# STM32WBA55 register map
File version: 1.0
CPU: CM33 r0p1, little endian, MPU, FPU, 4 interrupt priority bits
Registers are 32-bit, read-write, reset 0x0 unless marked. A register's access mark holds for its fields unless they carry their own. Offsets are from the block's base; [hi:lo] are bit positions; {n}, {i} and the like mark numbered series; 'fields as' and 'values as' point back to an identical list.

## I2C — Inter-integrated circuit
Base 0x40005400
Same registers: I2C3 0x46002800, SEC_I2C1 0x50005400, SEC_I2C3 0x56002800
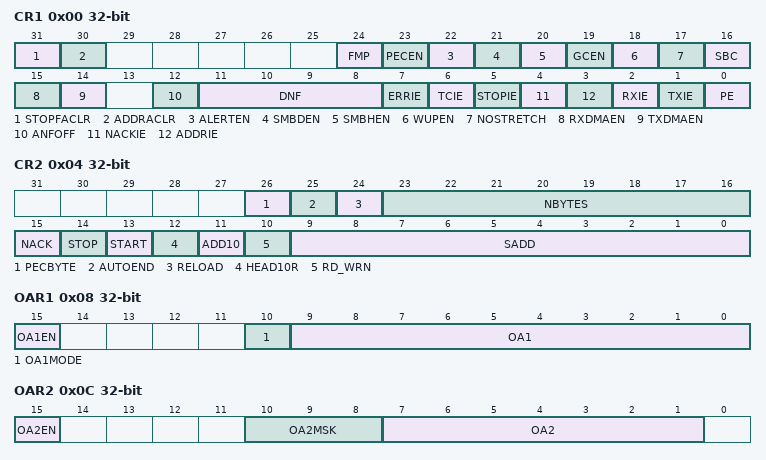
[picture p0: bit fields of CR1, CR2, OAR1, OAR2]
0x00 CR1 — I2C control register 1
  [31] STOPFACLR — STOP detection flag (STOPF) automatic clear
    0=Disabled (STOPF flag is set by hardware, cleared by software); 1=Enabled (STOPF flag remains cleared by hardware)
  [30] ADDRACLR — Address match flag (ADDR) automatic clear
    0=Disabled (ADDR flag is set by hardware, cleared by software); 1=Enabled (ADDR flag remains cleared by hardware)
  [24] FMP — Fast-mode Plus 20 mA drive enable
    0=Disabled (20 mA I/O drive disabled); 1=Enabled (20 mA I/O drive enabled)
  [23] PECEN — PEC enable Note: If the SMBus feature is not supported, this bit is reserved and forced by hardware to '0'. Refer to Section 52.3: FMPI2C implementation.
    0=Disabled (PEC calculation disabled); 1=Enabled (PEC calculation enabled)
  [22] ALERTEN — SMBus alert enable Note: When ALERTEN=0, the SMBA pin can be used as a standard GPIO. Note: If the SMBus feature is not supported, this bit is reserved and forced by hardware to '0'. Refer to Section 52.3: FMPI2C implementation.
    0=Disabled (In device mode (SMBHEN=Disabled) Releases SMBA pin high and Alert Response Address Header disabled (0001100x) followed by NACK. In host mode (SMBHEN=Enabled) SMBus Alert pin (SMBA) not supported); 1=Enabled (In device mode (SMBHEN=Disabled) Drives SMBA pin low and Alert Response Address Header enabled (0001100x) followed by ACK.In host mode (SMBHEN=Enabled) SMBus Alert pin (SMBA) supported)
  [21] SMBDEN — SMBus device default address enable Note: If the SMBus feature is not supported, this bit is reserved and forced by hardware to '0'. Refer to Section 52.3: FMPI2C implementation.
    0=Disabled (Device default address disabled. Address 0b1100001x is NACKed); 1=Enabled (Device default address enabled. Address 0b1100001x is ACKed)
  [20] SMBHEN — SMBus host address enable Note: If the SMBus feature is not supported, this bit is reserved and forced by hardware to '0'. Refer to Section 52.3: FMPI2C implementation.
    0=Disabled (Host address disabled. Address 0b0001000x is NACKed); 1=Enabled (Host address enabled. Address 0b0001000x is ACKed)
  [19] GCEN — General call enable
    0=Disabled (General call disabled. Address 0b00000000 is NACKed); 1=Enabled (General call enabled. Address 0b00000000 is ACKed)
  [18] WUPEN — Wakeup from Stop mode enable Note: If the Wakeup from Stop mode feature is not supported, this bit is reserved and forced by hardware to '0'. Refer to Section 52.3: FMPI2C implementation. Note: WUPEN can be set only when DNF = '0000'
    0=Disabled (Wakeup from Stop mode disabled); 1=Enabled (Wakeup from Stop mode enabled)
  [17] NOSTRETCH — Clock stretching disable This bit is used to disable clock stretching in slave mode. It must be kept cleared in master mode. Note: This bit can only be programmed when the I2C is disabled (PE = 0).
    0=Enabled (Clock stretching enabled); 1=Disabled (Clock stretching disabled)
  [16] SBC — Slave byte control This bit is used to enable hardware byte control in slave mode.
    0=Disabled (Slave byte control disabled); 1=Enabled (Slave byte control enabled)
  [15] RXDMAEN — DMA reception requests enable
    0=Disabled (DMA mode disabled for reception); 1=Enabled (DMA mode enabled for reception)
  [14] TXDMAEN — DMA transmission requests enable
    0=Disabled (DMA mode disabled for transmission); 1=Enabled (DMA mode enabled for transmission)
  [12] ANFOFF — Analog noise filter OFF Note: This bit can only be programmed when the I2C is disabled (PE = 0).
    0=Enabled (Analog noise filter enabled); 1=Disabled (Analog noise filter disabled)
  [11:8] DNF — Digital noise filter These bits are used to configure the digital noise filter on SDA and SCL input. The digital filter, filters spikes with a length of up to DNF[3:0] * tsubI2CCLK/sub sub.../sub Note: If the analog filter is also enabled, the digital filter is added to the analog filter. Note: This filter can only be programmed when the I2C is disabled (PE = 0).
    0=NoFilter (Digital filter disabled); {v}=Filter{v} (Digital filter enabled and filtering capability up to {v} tI2CCLK) (v=1..15)
  [7] ERRIE — Error interrupts enable Note: Any of these errors generate an interrupt: Note: Arbitration Loss (ARLO) Note: Bus Error detection (BERR) Note: Overrun/Underrun (OVR) Note: Timeout detection (TIMEOUT) Note: PEC error detection (PECERR) Note: Alert pin event detection (ALERT)
    0=Disabled (Error detection interrupts disabled); 1=Enabled (Error detection interrupts enabled)
  [6] TCIE — Transfer Complete interrupt enable Note: Any of these events generate an interrupt: Note: Transfer Complete (TC) Note: Transfer Complete Reload (TCR)
    0=Disabled (Transfer Complete interrupt disabled); 1=Enabled (Transfer Complete interrupt enabled)
  [5] STOPIE — Stop detection Interrupt enable
    0=Disabled (Stop detection (STOPF) interrupt disabled); 1=Enabled (Stop detection (STOPF) interrupt enabled)
  [4] NACKIE — Not acknowledge received Interrupt enable
    0=Disabled (Not acknowledge (NACKF) received interrupts disabled); 1=Enabled (Not acknowledge (NACKF) received interrupts enabled)
  [3] ADDRIE — Address match Interrupt enable (slave only)
    0=Disabled (Address match (ADDR) interrupts disabled); 1=Enabled (Address match (ADDR) interrupts enabled)
  [2] RXIE — RX Interrupt enable
    0=Disabled (Receive (RXNE) interrupt disabled); 1=Enabled (Receive (RXNE) interrupt enabled)
  [1] TXIE — TX Interrupt enable
    0=Disabled (Transmit (TXIS) interrupt disabled); 1=Enabled (Transmit (TXIS) interrupt enabled)
  [0] PE — Peripheral enable Note: When PE = 0, the I2C SCL and SDA lines are released. Internal state machines and status bits are put back to their reset value. When cleared, PE must be kept low for at least 3 APB clock cycles.
    0=Disabled (Peripheral disabled); 1=Enabled (Peripheral enabled)
0x04 CR2 — I2C control register 2
  [26] PECBYTE write-1-sets — Packet error checking byte This bit is set by software, and cleared by hardware when the PEC is transferred, or when a STOP condition or an Address matched is received, also when PE = 0. Note: Writing '0' to this bit has no effect. Note: This bit has no effect when RELOAD is set. Note: This bit has no effect is slave mode when SBC=0. Note: If the SMBus feature is not supported, this bit is reserved and forced by hardware to '0'. Refer to Section 52.3: FMPI2C implementation.
    on read: 0=No PEC transfer; 1=Pec (PEC transmission/reception is requested) | on write: 1=Pec (PEC transmission/reception is requested)
  [25] AUTOEND — Automatic end mode (master mode) This bit is set and cleared by software. Note: This bit has no effect in slave mode or when the RELOAD bit is set.
    0=Software end mode: TC flag is set when NBYTES data are transferred, stretching SCL low; 1=Automatic end mode: a STOP condition is automatically sent when NBYTES data are transferred
  [24] RELOAD — NBYTES reload mode This bit is set and cleared by software.
    0=Completed (The transfer is completed after the NBYTES data transfer (STOP or RESTART will follow)); 1=NotCompleted (The transfer is not completed after the NBYTES data transfer (NBYTES will be reloaded))
  [23:16] NBYTES — Number of bytes The number of bytes to be transmitted/received is programmed there. This field is don't care in slave mode with SBC=0. Note: Changing these bits when the START bit is set is not allowed.
  [15] NACK write-1-sets — NACK generation (slave mode) The bit is set by software, cleared by hardware when the NACK is sent, or when a STOP condition or an Address matched is received, or when PE = 0. Note: Writing '0' to this bit has no effect. Note: This bit is used in slave mode only: in master receiver mode, NACK is automatically generated after last byte preceding STOP or RESTART condition, whatever the NACK bit value. Note: When an overrun occurs in slave receiver NOSTRETCH mode, a NACK is automatically generated whatever the NACK bit value. Note: When hardware PEC checking is enabled (PECBYTE=1), the PEC acknowledge value does not depend on the NACK value.
    on read: 0=Ack (an ACK is sent after current received byte); 1=Nack (a NACK is sent after current received byte) | on write: 1=Nack (a NACK is sent after current received byte)
  [14] STOP write-1-sets — Stop generation (master mode) The bit is set by software, cleared by hardware when a STOP condition is detected, or when PE = 0. In Master Mode: Note: Writing '0' to this bit has no effect.
    on read: 0=No Stop generation; 1=Stop generation after current byte transfer | on write: 1=Stop generation after current byte transfer
  [13] START write-1-sets — Start generation This bit is set by software, and cleared by hardware after the Start followed by the address sequence is sent, by an arbitration loss, by an address matched in slave mode, by a timeout error detection, or when PE = 0. If the I2C is already in master mode with AUTOEND = 0, setting this bit generates a Repeated Start condition when RELOAD=0, after the end of the NBYTES transfer. Otherwise setting this bit generates a START condition once the bus is free. Note: Writing '0' to this bit has no effect. Note: The START bit can be set even if the bus is BUSY or I2C is in slave mode. Note: This bit has no effect when RELOAD is set.
    on read: 0=No Start generation; 1=Start (Restart/Start generation) | on write: 1=Start (Restart/Start generation)
  [12] HEAD10R — 10-bit address header only read direction (master receiver mode) Note: Changing this bit when the START bit is set is not allowed.
    0=Complete (The master sends the complete 10 bit slave address read sequence); 1=Partial (The master only sends the 1st 7 bits of the 10 bit address, followed by Read direction)
  [11] ADD10 — 10-bit addressing mode (master mode) Note: Changing this bit when the START bit is set is not allowed.
    0=Bit7 (The master operates in 7-bit addressing mode); 1=Bit10 (The master operates in 10-bit addressing mode)
  [10] RD_WRN — Transfer direction (master mode) Note: Changing this bit when the START bit is set is not allowed.
    0=Write (Master requests a write transfer); 1=Read (Master requests a read transfer)
  [9:0] SADD — Slave address (master mode) In 7-bit addressing mode (ADD10 = 0): SADD[7:1] should be written with the 7-bit slave address to be sent. The bits SADD[9], SADD[8] and SADD[0] are don't care. In 10-bit addressing mode (ADD10 = 1): SADD[9:0] should be written with the 10-bit slave address to be sent. Note: Changing these bits when the START bit is set is not allowed.
0x08 OAR1 — I2C own address 1 register
  [15] OA1EN — Own Address 1 enable
    0=Disabled (Own address 1 disabled. The received slave address OA1 is NACKed); 1=Enabled (Own address 1 enabled. The received slave address OA1 is ACKed)
  [10] OA1MODE — Own Address 1 10-bit mode Note: This bit can be written only when OA1EN=0.
    0=Bit7 (Own address 1 is a 7-bit address); 1=Bit10 (Own address 1 is a 10-bit address)
  [9:0] OA1 — Interface own slave address 7-bit addressing mode: OA1[7:1] contains the 7-bit own slave address. The bits OA1[9], OA1[8] and OA1[0] are don't care. 10-bit addressing mode: OA1[9:0] contains the 10-bit own slave address. Note: These bits can be written only when OA1EN=0.
0x0C OAR2 — I2C own address 2 register
  [15] OA2EN — Own Address 2 enable
    0=Disabled (Own address 2 disabled. The received slave address OA2 is NACKed); 1=Enabled (Own address 2 enabled. The received slave address OA2 is ACKed)
  [10:8] OA2MSK — Own Address 2 masks Note: These bits can be written only when OA2EN=0. Note: As soon as OA2MSK is not equal to 0, the reserved I2C addresses (0b0000xxx and 0b1111xxx) are not acknowledged even if the comparison matches.
    0=NoMask; 1=Mask1 (OA2[1] is masked and don’t care. Only OA2[7:2] are compared); {v}=Mask{v} (OA2[{v}:1] are masked and don’t care. Only OA2[7:{v+1}] are compared) (v=2..5); 6=Mask6 (OA2[6:1] are masked and don’t care. Only OA2[7] is compared.); 7=Mask7 (OA2[7:1] are masked and don’t care. No comparison is done, and all (except reserved) 7-bit received addresses are acknowledged)
  [7:1] OA2 — Interface address 7-bit addressing mode: 7-bit address Note: These bits can be written only when OA2EN=0.
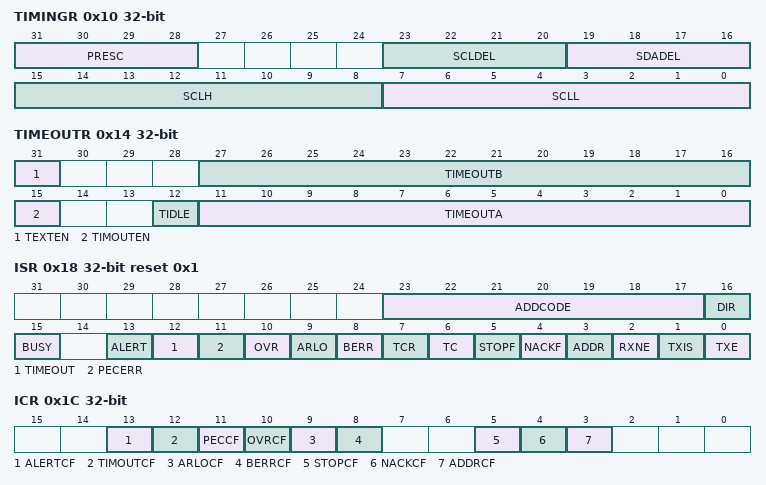
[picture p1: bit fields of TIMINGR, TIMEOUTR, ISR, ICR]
0x10 TIMINGR — I2C timing register
  [31:28] PRESC — Timing prescaler This field is used to prescale i2c_ker_ck in order to generate the clock period tsubPRESC /subused for data setup and hold counters (refer to FMPI2C timings on page 1928) and for SCL high and low level counters (refer to FMPI2C master initialization on page 1951). tsubPRESC /sub= (PRESC+1) x tsubI2CCLK/sub
  [23:20] SCLDEL — Data setup time This field is used to generate a delay tsubSCLDEL /subbetween SDA edge and SCL rising edge. In master mode and in slave mode with NOSTRETCH = 0, the SCL line is stretched low during tsubSCLDEL/sub. tsubSCLDEL /sub= (SCLDEL+1) x tsubPRESC/sub Note: tsubSCLDEL/sub is used to generate tsubSU:DAT /subtiming.
  [19:16] SDADEL — Data hold time This field is used to generate the delay tsubSDADEL /subbetween SCL falling edge and SDA edge. In master mode and in slave mode with NOSTRETCH = 0, the SCL line is stretched low during tsubSDADEL/sub. tsubSDADEL/sub= SDADEL x tsubPRESC/sub Note: SDADEL is used to generate tsubHD:DAT /subtiming.
  [15:8] SCLH — SCL high period (master mode) This field is used to generate the SCL high period in master mode. tsubSCLH /sub= (SCLH+1) x tsubPRESC/sub Note: SCLH is also used to generate tsubSU:STO /suband tsubHD:STA /subtiming.
  [7:0] SCLL — SCL low period (master mode) This field is used to generate the SCL low period in master mode. tsubSCLL /sub= (SCLL+1) x tsubPRESC/sub Note: SCLL is also used to generate tsubBUF /suband tsubSU:STA /subtimings.
0x14 TIMEOUTR — I2C timeout register
  [31] TEXTEN — Extended clock timeout enable
    0=Disabled (Extended clock timeout detection is disabled); 1=Enabled (Extended clock timeout detection is enabled)
  [27:16] TIMEOUTB — Bus timeout B This field is used to configure the cumulative clock extension timeout: In master mode, the master cumulative clock low extend time (tsubLOW:MEXT/sub) is detected In slave mode, the slave cumulative clock low extend time (tsubLOW:SEXT/sub) is detected tsubLOW:EXT/sub= (TIMEOUTB+1) x 2048 x tsubI2CCLK/sub Note: These bits can be written only when TEXTEN=0.
  [15] TIMOUTEN — Clock timeout enable
    0=Disabled (SCL timeout detection is disabled); 1=Enabled (SCL timeout detection is enabled)
  [12] TIDLE — Idle clock timeout detection Note: This bit can be written only when TIMOUTEN=0.
    0=Disabled (TIMEOUTA is used to detect SCL low timeout); 1=Enabled (TIMEOUTA is used to detect both SCL and SDA high timeout (bus idle condition))
  [11:0] TIMEOUTA — Bus Timeout A This field is used to configure: The SCL low timeout condition tsubTIMEOUT/sub when TIDLE=0 tsubTIMEOUT/sub= (TIMEOUTA+1) x 2048 x tsubI2CCLK/sub The bus idle condition (both SCL and SDA high) when TIDLE=1 tsubIDLE/sub= (TIMEOUTA+1) x 4 x tsubI2CCLK/sub Note: These bits can be written only when TIMOUTEN=0.
0x18 ISR access per field reset 0x1 — I2C interrupt and status register
  [23:17] ADDCODE ro — Address match code (Slave mode) These bits are updated with the received address when an address match event occurs (ADDR = 1). In the case of a 10-bit address, ADDCODE provides the 10-bit header followed by the 2 MSBs of the address.
  [16] DIR ro — Transfer direction (Slave mode) This flag is updated when an address match event occurs (ADDR = 1).
    0=Write transfer, slave enters receiver mode; 1=Read transfer, slave enters transmitter mode
  [15] BUSY ro — Bus busy This flag indicates that a communication is in progress on the bus. It is set by hardware when a START condition is detected. It is cleared by hardware when a STOP condition is detected, or when PE = 0.
    0=NotBusy (No communication is in progress on the bus); 1=Busy (A communication is in progress on the bus)
  [13] ALERT ro — SMBus alert This flag is set by hardware when SMBHEN=1 (SMBus host configuration), ALERTEN=1 and a SMBALERT event (falling edge) is detected on SMBA pin. It is cleared by software by setting the ALERTCF bit. Note: This bit is cleared by hardware when PE = 0. Note: If the SMBus feature is not supported, this bit is reserved and forced by hardware to '0'. Refer to Section 52.3: FMPI2C implementation.
    0=NoAlert (SMBA alert is not detected); 1=Alert (SMBA alert event is detected on SMBA pin)
  [12] TIMEOUT ro — Timeout or tsubLOW/sub detection flag This flag is set by hardware when a timeout or extended clock timeout occurred. It is cleared by software by setting the TIMEOUTCF bit. Note: This bit is cleared by hardware when PE = 0. Note: If the SMBus feature is not supported, this bit is reserved and forced by hardware to '0'. Refer to Section 52.3: FMPI2C implementation.
    0=No timeout occured; 1=Timeout occured
  [11] PECERR ro — PEC Error in reception This flag is set by hardware when the received PEC does not match with the PEC register content. A NACK is automatically sent after the wrong PEC reception. It is cleared by software by setting the PECCF bit. Note: This bit is cleared by hardware when PE = 0. Note: If the SMBus feature is not supported, this bit is reserved and forced by hardware to '0'. Refer to Section 52.3: FMPI2C implementation.
    0=Match (Received PEC does match with PEC register); 1=NoMatch (Received PEC does not match with PEC register)
  [10] OVR ro — Overrun/Underrun (slave mode) This flag is set by hardware in slave mode with NOSTRETCH = 1, when an overrun/underrun error occurs. It is cleared by software by setting the OVRCF bit. Note: This bit is cleared by hardware when PE = 0.
    0=No overrun/underrun error occurs; 1=Overrun (slave mode with NOSTRETCH=1, when an overrun/underrun error occurs)
  [9] ARLO ro — Arbitration lost This flag is set by hardware in case of arbitration loss. It is cleared by software by setting the ARLOCF bit. Note: This bit is cleared by hardware when PE = 0.
    0=NotLost (No arbitration lost); 1=Lost (Arbitration lost)
  [8] BERR ro — Bus error This flag is set by hardware when a misplaced Start or STOP condition is detected whereas the peripheral is involved in the transfer. The flag is not set during the address phase in slave mode. It is cleared by software by setting BERRCF bit. Note: This bit is cleared by hardware when PE = 0.
    0=NoError (No bus error); 1=Error (Misplaced Start and Stop condition is detected)
  [7] TCR ro — Transfer Complete Reload This flag is set by hardware when RELOAD=1 and NBYTES data have been transferred. It is cleared by software when NBYTES is written to a non-zero value. Note: This bit is cleared by hardware when PE = 0. Note: This flag is only for master mode, or for slave mode when the SBC bit is set.
    0=NotComplete (Transfer is not complete); 1=Complete (NBYTES has been transfered)
  [6] TC ro — Transfer Complete (master mode) This flag is set by hardware when RELOAD=0, AUTOEND=0 and NBYTES data have been transferred. It is cleared by software when START bit or STOP bit is set. Note: This bit is cleared by hardware when PE = 0.
    values as TCR
  [5] STOPF ro — Stop detection flag This flag is set by hardware when a STOP condition is detected on the bus and the peripheral is involved in this transfer: either as a master, provided that the STOP condition is generated by the peripheral. or as a slave, provided that the peripheral has been addressed previously during this transfer. It is cleared by software by setting the STOPCF bit. Note: This bit is cleared by hardware when PE = 0.
    0=No Stop condition detected; 1=Stop condition detected
  [4] NACKF ro — Not Acknowledge received flag This flag is set by hardware when a NACK is received after a byte transmission. It is cleared by software by setting the NACKCF bit. Note: This bit is cleared by hardware when PE = 0.
    0=No NACK has been received; 1=NACK has been received
  [3] ADDR ro — Address matched (slave mode) This bit is set by hardware as soon as the received slave address matched with one of the enabled slave addresses. It is cleared by software by setting ADDRCF bit. Note: This bit is cleared by hardware when PE = 0.
    0=NotMatch (Adress mismatched or not received); 1=Match (Received slave address matched with one of the enabled slave addresses)
  [2] RXNE ro — Receive data register not empty (receivers) This bit is set by hardware when the received data is copied into the I2C_RXDR register, and is ready to be read. It is cleared when I2C_RXDR is read. Note: This bit is cleared by hardware when PE = 0.
    0=Empty (The RXDR register is empty); 1=NotEmpty (Received data is copied into the RXDR register, and is ready to be read)
  [1] TXIS rw write-1-sets — Transmit interrupt status (transmitters) This bit is set by hardware when the I2C_TXDR register is empty and the data to be transmitted must be written in the I2C_TXDR register. It is cleared when the next data to be sent is written in the I2C_TXDR register. This bit can be written to '1' by software when NOSTRETCH = 1 only, in order to generate a TXIS event (interrupt if TXIE=1 or DMA request if TXDMAEN = 1). Note: This bit is cleared by hardware when PE = 0.
    on read: 0=NotEmpty (The TXDR register is not empty); 1=Empty (The TXDR register is empty and the data to be transmitted must be written in the TXDR register) | on write: 1=Trigger (Generate a TXIS event)
  [0] TXE rw write-1-sets — Transmit data register empty (transmitters) This bit is set by hardware when the I2C_TXDR register is empty. It is cleared when the next data to be sent is written in the I2C_TXDR register. This bit can be written to '1' by software in order to flush the transmit data register I2C_TXDR. Note: This bit is set by hardware when PE = 0.
    on read: 0=NotEmpty (TXDR register not empty); 1=Empty (TXDR register empty) | on write: 1=Flush the transmit data register
0x1C ICR wo — I2C interrupt clear register
  [13] ALERTCF write-1-clears — Alert flag clear Writing 1 to this bit clears the ALERT flag in the I2C_ISR register. Note: If the SMBus feature is not supported, this bit is reserved and forced by hardware to '0'. Refer to Section 52.3: FMPI2C implementation.
    1=Clears the ALERT flag in ISR register
  [12] TIMOUTCF write-1-clears — Timeout detection flag clear Writing 1 to this bit clears the TIMEOUT flag in the I2C_ISR register. Note: If the SMBus feature is not supported, this bit is reserved and forced by hardware to '0'. Refer to Section 52.3: FMPI2C implementation.
    1=Clears the TIMOUT flag in ISR register
  [11] PECCF write-1-clears — PEC Error flag clear Writing 1 to this bit clears the PECERR flag in the I2C_ISR register. Note: If the SMBus feature is not supported, this bit is reserved and forced by hardware to '0'. Refer to Section 52.3: FMPI2C implementation.
    1=Clears the PEC flag in ISR register
  [10] OVRCF write-1-clears — Overrun/Underrun flag clear Writing 1 to this bit clears the OVR flag in the I2C_ISR register.
    1=Clears the OVR flag in ISR register
  [9] ARLOCF write-1-clears — Arbitration lost flag clear Writing 1 to this bit clears the ARLO flag in the I2C_ISR register.
    1=Clears the ARLO flag in ISR register
  [8] BERRCF write-1-clears — Bus error flag clear Writing 1 to this bit clears the BERRF flag in the I2C_ISR register.
    1=Clears the BERR flag in ISR register
  [5] STOPCF write-1-clears — STOP detection flag clear Writing 1 to this bit clears the STOPF flag in the I2C_ISR register.
    1=Clears the STOP flag in ISR register
  [4] NACKCF write-1-clears — Not Acknowledge flag clear Writing 1 to this bit clears the NACKF flag in I2C_ISR register.
    1=Clears the NACK flag in ISR register
  [3] ADDRCF write-1-clears — Address matched flag clear Writing 1 to this bit clears the ADDR flag in the I2C_ISR register. Writing 1 to this bit also clears the START bit in the I2C_CR2 register.
    1=Clears the ADDR flag in ISR register
0x20 PECR ro — I2C PEC register
  [7:0] PEC — Packet error checking register This field contains the internal PEC when PECEN=1. The PEC is cleared by hardware when PE = 0.
0x24 RXDR ro — I2C receive data register
  [7:0] RXDATA — 8-bit receive data Data byte received from the Isup2/supC bus
0x28 TXDR — I2C transmit data register
  [7:0] TXDATA — 8-bit transmit data Data byte to be transmitted to the Isup2/supC bus Note: These bits can be written only when TXE = 1.
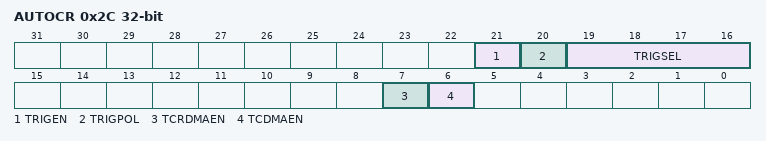
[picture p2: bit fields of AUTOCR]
0x2C AUTOCR — I2C Autonomous mode control register
  [21] TRIGEN — Trigger enable When a trigger is detected, a START condition is sent and the transfer is launched as defined in I2C_CR2.
  [20] TRIGPOL — Trigger polarity Note: This bit can be written only when PE = 0
  [19:16] TRIGSEL — Trigger selection (refer to Section 52.4.3: FMPI2C pins and internal signals I2C interconnections tables). ... Note: This bit can be written only when PE = 0
  [7] TCRDMAEN — DMA request enable on Transfer Complete Reload event
  [6] TCDMAEN — DMA request enable on Transfer Complete event
